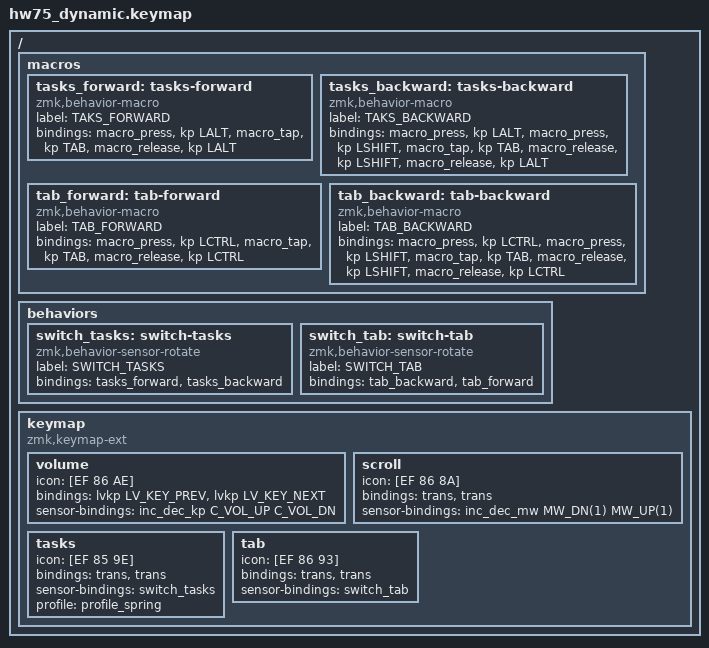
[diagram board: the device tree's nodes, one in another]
/*
 * Copyright (c) 2022 The ZMK Contributors
 * SPDX-License-Identifier: MIT
 */

#include <behaviors.dtsi>
#include <behaviors/lvgl_key_press.dtsi>
#include <behaviors/sensor_rotate_mouse_wheel.dtsi>
#include <dt-bindings/zmk/keys.h>
#include <dt-bindings/zmk/rgb.h>
#include <dt-bindings/zmk/lvgl.h>
#include <dt-bindings/zmk/mouse.h>

/ {
	macros {
		tasks_forward: tasks-forward {
			label = "TAKS_FORWARD";
			compatible = "zmk,behavior-macro";
			#binding-cells = <0>;
			bindings = <&macro_press   &kp LALT>,
				   <&macro_tap     &kp TAB>,
				   <&macro_release &kp LALT>;
		};

		tasks_backward: tasks-backward {
			label = "TAKS_BACKWARD";
			compatible = "zmk,behavior-macro";
			#binding-cells = <0>;
			bindings = <&macro_press   &kp LALT>,
				   <&macro_press   &kp LSHIFT>,
				   <&macro_tap     &kp TAB>,
				   <&macro_release &kp LSHIFT>,
				   <&macro_release &kp LALT>;
		};

		tab_forward: tab-forward {
			label = "TAB_FORWARD";
			compatible = "zmk,behavior-macro";
			#binding-cells = <0>;
			bindings = <&macro_press   &kp LCTRL>,
				   <&macro_tap     &kp TAB>,
				   <&macro_release &kp LCTRL>;
		};

		tab_backward: tab-backward {
			label = "TAB_BACKWARD";
			compatible = "zmk,behavior-macro";
			#binding-cells = <0>;
			bindings = <&macro_press   &kp LCTRL>,
				   <&macro_press   &kp LSHIFT>,
				   <&macro_tap     &kp TAB>,
				   <&macro_release &kp LSHIFT>,
				   <&macro_release &kp LCTRL>;
		};
	};

	behaviors {
		switch_tasks: switch-tasks {
			compatible = "zmk,behavior-sensor-rotate";
			label = "SWITCH_TASKS";
			#sensor-binding-cells = <0>;
			bindings = <&tasks_forward>, <&tasks_backward>;
		};

		switch_tab: switch-tab {
			compatible = "zmk,behavior-sensor-rotate";
			label = "SWITCH_TAB";
			#sensor-binding-cells = <0>;
			bindings = <&tab_backward>, <&tab_forward>;
		};
	};

	keymap {
		compatible = "zmk,keymap-ext", "zmk,keymap";

		volume {
			label = "音量";
			icon = [EF 86 AE];
			bindings = <&lvkp LV_KEY_PREV &lvkp LV_KEY_NEXT>;
			sensor-bindings = <&inc_dec_kp C_VOL_UP C_VOL_DN>;
		};

		scroll {
			label = "滾動";
			icon = [EF 86 8A];
			bindings = <&trans &trans>;
			sensor-bindings = <&inc_dec_mw MW_DN(1) MW_UP(1)>;
		};

		tasks {
			label = "窗口";
			icon = [EF 85 9E];
			bindings = <&trans &trans>;
			sensor-bindings = <&switch_tasks>;
			profile = <&profile_spring>;
		};

		tab {
			label = "分頁";
			icon = [EF 86 93];
			bindings = <&trans &trans>;
			sensor-bindings = <&switch_tab>;
		};
	};
};
